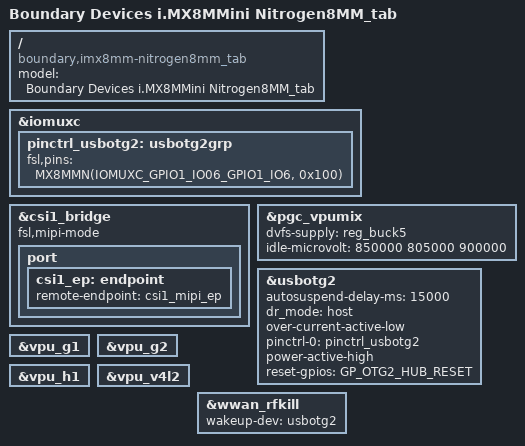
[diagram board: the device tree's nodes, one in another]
// SPDX-License-Identifier: (GPL-2.0+ OR MIT)
/*
 * Copyright 2018 Boundary Devices
 */

/dts-v1/;
#define MX8MMN(a, b)	MX8MM_##a b
#define IMX8MMN(a)	IMX8MM_##a
#include "imx8mm.dtsi"
#include "imx8mmn-nitrogen8mm_tab.dtsi"

&iomuxc {
	pinctrl_usbotg2: usbotg2grp {
		fsl,pins = <
#define GP_OTG2_HUB_RESET        <&gpio1 6 GPIO_ACTIVE_LOW>
			MX8MMN(IOMUXC_GPIO1_IO06_GPIO1_IO6, 0x100)
		>;
	};
};

/ {
	model = "Boundary Devices i.MX8MMini Nitrogen8MM_tab";
	compatible = "boundary,imx8mm-nitrogen8mm_tab", "fsl,imx8mm";
};

&csi1_bridge {
	fsl,mipi-mode;
	status = "okay";

	port {
		csi1_ep: endpoint {
			remote-endpoint = <&csi1_mipi_ep>;
		};
	};
};

&pgc_vpumix {
	dvfs-supply = <&reg_buck5>;
	idle-microvolt = <850000 805000 900000>;
};

&usbotg2 {
	autosuspend-delay-ms = <15000>;
	dr_mode = "host";
	over-current-active-low;
	pinctrl-names = "default";
	pinctrl-0 = <&pinctrl_usbotg2>;
	power-active-high;
	reset-gpios = GP_OTG2_HUB_RESET;
	status = "okay";
};

&vpu_g1 {
	status = "okay";
};

&vpu_g2 {
	status = "okay";
};

&vpu_h1 {
	status = "okay";
};

&vpu_v4l2 {
	status = "okay";
};

&wwan_rfkill {
	wakeup-dev = <&usbotg2>;
};
